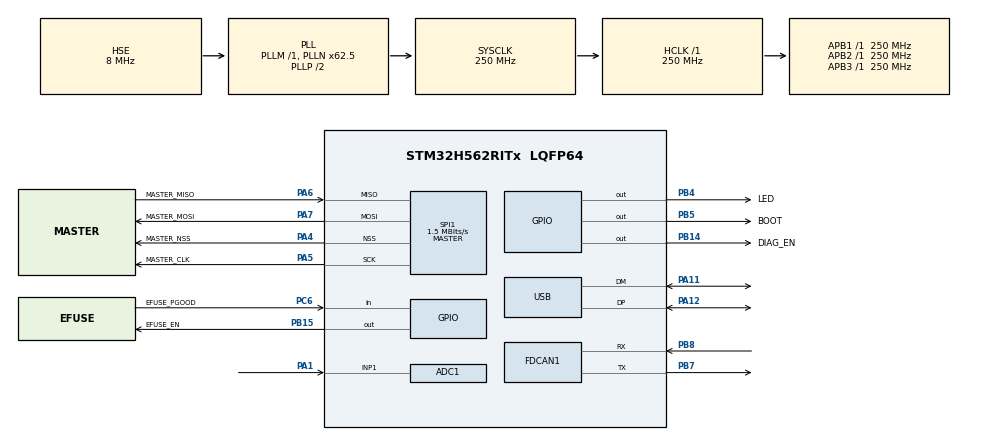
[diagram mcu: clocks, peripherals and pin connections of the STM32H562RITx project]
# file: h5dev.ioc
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ADC1.Channel-0\#ChannelRegularConversion=ADC_CHANNEL_1
ADC1.ContinuousConvMode=DISABLE
ADC1.ConversionDataManagement=ADC_CONVERSIONDATA_DMA_CIRCULAR
ADC1.DMAContinuousRequests=ENABLE
ADC1.EOCSelection=ADC_EOC_SEQ_CONV
ADC1.ExternalTrigConv=ADC_EXTERNALTRIG_T3_TRGO
ADC1.MonitoredBy-0\#ChannelRegularConversion=__NULL
ADC1.NbrOfConversionFlag=1
ADC1.OffsetNumber-0\#ChannelRegularConversion=ADC_OFFSET_NONE
ADC1.Rank-0\#ChannelRegularConversion=1
ADC1.SamplingTime-0\#ChannelRegularConversion=ADC_SAMPLETIME_2CYCLES_5
ADC1.master=1
BOOTPATH.BootPathName=LEGACY
BOOTPATH.UserSelectedBootPath=LEGACY
CORTEX_M33_NS.userName=CORTEX_M33
FDCAN1.AutoRetransmission=ENABLE
FDCAN1.CalculateBaudRateNominal=1000000
FDCAN1.CalculateTimeBitNominal=1000
FDCAN1.CalculateTimeQuantumNominal=62.5
FDCAN1.DataPrescaler=3
FDCAN1.DataSyncJumpWidth=2
FDCAN1.DataTimeSeg1=5
FDCAN1.DataTimeSeg2=2
FDCAN1.ExtFiltersNbr=1
FDCAN1.FrameFormat=FDCAN_FRAME_FD_NO_BRS
FDCAN1.Mode=FDCAN_MODE_NORMAL
FDCAN1.NominalPrescaler=6
FDCAN1.NominalSyncJumpWidth=2
FDCAN1.NominalTimeSeg1=13
FDCAN1.NominalTimeSeg2=2
FDCAN1.StdFiltersNbr=1
GPDMA1.CIRCULARMODE_GPDMACH0=ENABLE
GPDMA1.DESTDATAWIDTH_GPDMACH0=DMA_DEST_DATAWIDTH_HALFWORD
GPDMA1.IPHANDLE_GPDMACH0-SIMPLEREQUEST_GPDMACH0=__NULL
GPDMA1.REQUEST_GPDMACH0=GPDMA1_REQUEST_ADC1
GPDMA1.SRCDATAWIDTH_GPDMACH0=DMA_SRC_DATAWIDTH_HALFWORD
GPDMA1.TRIGGERPOLARITY_GPDMACH0=DMA_TRIG_POLARITY_MASKED
Mcu.Family=STM32H5
Mcu.Name=STM32H562RITx
Mcu.Package=LQFP64
NVIC.ADC1_IRQn=true\:5\:0\:true\:false\:true\:true\:true\:true
NVIC.FDCAN1_IT0_IRQn=true\:5\:0\:true\:false\:true\:true\:true\:true
NVIC.FDCAN1_IT1_IRQn=true\:5\:0\:true\:false\:true\:true\:true\:true
NVIC.GPDMA1_Channel0_IRQn=true\:5\:0\:true\:false\:true\:true\:true\:true
NVIC.PriorityGroup=NVIC_PRIORITYGROUP_4
NVIC.RCC_IRQn=true\:5\:0\:true\:false\:true\:true\:false\:true
NVIC.TIM3_IRQn=true\:5\:0\:true\:false\:true\:true\:true\:true
NVIC.TIM6_IRQn=true\:15\:0\:false\:false\:true\:false\:true\:true
NVIC.TimeBase=TIM6_IRQn
NVIC.TimeBaseIP=TIM6
NVIC.USB_DRD_FS_IRQn=true\:0\:0\:false\:false\:true\:true\:true\:true
PA1.Signal=ADCx_INP1
PA11.Mode=Device
PA11.Signal=USB_DM
PA12.Mode=Device
PA12.Signal=USB_DP
PA13(JTMS/SWDIO).GPIO_Label=SWDIO
PA13(JTMS/SWDIO).Mode=Trace_Asynchronous_SW
PA13(JTMS/SWDIO).Signal=DEBUG_JTMS-SWDIO
PA14(JTCK/SWCLK).GPIO_Label=SWCLK
PA14(JTCK/SWCLK).Mode=Trace_Asynchronous_SW
PA14(JTCK/SWCLK).Signal=DEBUG_JTCK-SWCLK
PA4.GPIO_Label=MASTER_NSS
PA4.Mode=NSS_Signal_Hard_Output
PA4.Signal=SPI1_NSS
PA5.GPIO_Label=MASTER_CLK
PA5.Mode=Full_Duplex_Master
PA5.Signal=SPI1_SCK
PA6.GPIO_Label=MASTER_MISO
PA6.Mode=Full_Duplex_Master
PA6.Signal=SPI1_MISO
PA7.GPIO_Label=MASTER_MOSI
PA7.Mode=Full_Duplex_Master
PA7.Signal=SPI1_MOSI
PA9.GPIO_Label=SLAVE_CLK
PA9.Signal=SPI2_SCK
PB14.GPIO_Label=DIAG_EN
PB14.Signal=GPIO_Output
PB15.GPIO_Label=EFUSE_EN
PB15.Signal=GPIO_Output
PB3(JTDO/TRACESWO).GPIO_Label=SWO
PB3(JTDO/TRACESWO).Mode=Trace_Asynchronous_SW
PB3(JTDO/TRACESWO).Signal=DEBUG_JTDO-SWO
PB4(NJTRST).GPIO_Label=LED
PB4(NJTRST).PinState=GPIO_PIN_RESET
PB4(NJTRST).Signal=GPIO_Output
PB5.GPIO_Label=BOOT
PB5.PinState=GPIO_PIN_RESET
PB5.Signal=GPIO_Output
PB7.Mode=FDCAN_Activate
PB7.Signal=FDCAN1_TX
PB8.Mode=FDCAN_Activate
PB8.Signal=FDCAN1_RX
PC14-OSC32_IN(OSC32_IN).Mode=LSE-External-Oscillator
PC14-OSC32_IN(OSC32_IN).Signal=RCC_OSC32_IN
PC15-OSC32_OUT(OSC32_OUT).Mode=LSE-External-Oscillator
PC15-OSC32_OUT(OSC32_OUT).Signal=RCC_OSC32_OUT
PC6.GPIO_Label=EFUSE_PGOOD
PC6.Signal=GPIO_Input
PH0-OSC_IN(PH0).Mode=HSE-External-Oscillator
PH0-OSC_IN(PH0).Signal=RCC_OSC_IN
PH1-OSC_OUT(PH1).Mode=HSE-External-Oscillator
PH1-OSC_OUT(PH1).Signal=RCC_OSC_OUT
ProjectManager.HeapSize=0x0
ProjectManager.StackSize=0x400
ProjectManager.TargetToolchain=CMake
RCC.ADCCLockSelection=RCC_ADCDACCLKSOURCE_PLL2R
RCC.ADCFreq_Value=96000000
RCC.AHBFreq_Value=250000000
RCC.APB1Freq_Value=250000000
RCC.APB1TimFreq_Value=250000000
RCC.APB2Freq_Value=250000000
RCC.APB2TimFreq_Value=250000000
RCC.APB3Freq_Value=250000000
RCC.CSI_VALUE=4000000
RCC.CortexFreq_Value=250000000
RCC.EPOD_VALUE=8000000
RCC.FDCANClockSelection=RCC_FDCANCLKSOURCE_PLL2Q
RCC.HCLKFreq_Value=250000000
RCC.HSE_VALUE=8000000
RCC.HSI48_VALUE=48000000
RCC.HSIDiv=RCC_HSI_DIV1
RCC.HSI_VALUE=64000000
RCC.LSIRC_VALUE=32000
RCC.PLL2FRACN=0
RCC.PLL2N=24
RCC.PLL2Source=RCC_PLL2_SOURCE_HSE
RCC.PLL3FRACN=4096
RCC.PLL3N=37
RCC.PLL3P=50
RCC.PLLFRACN=4096
RCC.PLLN=62
RCC.PLLSourceVirtual=RCC_PLL1_SOURCE_HSE
RCC.SPI1CLockSelection=RCC_SPI1CLKSOURCE_PLL3P
RCC.SPI2CLockSelection=RCC_SPI2CLKSOURCE_PLL3P
RCC.SYSCLKFreq_VALUE=250000000
RCC.SYSCLKSource=RCC_SYSCLKSOURCE_PLLCLK
RCC.USBFreq_Value=48000000
RCC.VCOOutputFreq_Value=500000000
SH.ADCx_INP1.0=ADC1_INP1,IN1-Single-Ended
SPI1.CalculateBaudRate=1.5 MBits/s
SPI1.DataSize=SPI_DATASIZE_8BIT
SPI1.Direction=SPI_DIRECTION_2LINES
SPI1.Mode=SPI_MODE_MASTER
SPI1.VirtualNSS=VM_NSSHARD
SPI1.VirtualType=VM_MASTER
TIM3.AutoReloadPreload=TIM_AUTORELOAD_PRELOAD_ENABLE
TIM3.PeriodNoDither=47999
TIM3.TIM_MasterOutputTrigger=TIM_TRGO_UPDATE
USB.VirtualMode=Device_Only
VP_BOOTPATH_VS_BOOTPATH.Mode=BP_Activate
VP_CORDIC_VS_CORDIC.Mode=CORDIC_Activate
VP_CORTEX_M33_NS_VS_Ext.Mode=External_Mode
VP_GPDMA1_VS_GPDMACH0.Mode=SIMPLEREQUEST_GPDMACH0
VP_MEMORYMAP_VS_MEMORYMAP.Mode=CurAppReg
VP_PWR_VS_LPOM.Mode=PowerOptimisation
VP_PWR_VS_SECSignals.Mode=Security/Privilege
VP_RTC_VS_RTC_Activate.Mode=RTC_Enabled
VP_SYS_VS_tim6.Mode=TIM6
VP_TIM3_VS_ClockSourceINT.Mode=Internal
board=custom

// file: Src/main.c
/* USER CODE BEGIN Header */
/**
 ******************************************************************************
 * @file           : main.c
 * @brief          : Main program body
 ******************************************************************************
 * @attention
 *
 * Copyright (c) 2026 STMicroelectronics.
 * All rights reserved.
 *
 * This software is licensed under terms that can be found in the LICENSE file
 * in the root directory of this software component.
 * If no LICENSE file comes with this software, it is provided AS-IS.
 *
 ******************************************************************************
 */
/* USER CODE END Header */
#include "main.h"

/* USER CODE BEGIN Includes */
#include "tasks.h"
#include "hw_usb.h"
#include "hw_error.hpp"
#include "SEGGER_SYSVIEW.h"
/* USER CODE END Includes */

ADC_HandleTypeDef hadc1;
DMA_NodeTypeDef   Node_GPDMA1_Channel0;
DMA_QListTypeDef  List_GPDMA1_Channel0;
DMA_HandleTypeDef handle_GPDMA1_Channel0;

CORDIC_HandleTypeDef hcordic;

FDCAN_HandleTypeDef hfdcan1;

RTC_HandleTypeDef hrtc;

SPI_HandleTypeDef hspi1;

TIM_HandleTypeDef htim3;

PCD_HandleTypeDef hpcd_USB_DRD_FS;

void        SystemClock_Config(void);
void        PeriphCommonClock_Config(void);
static void MX_GPIO_Init(void);
static void MX_GPDMA1_Init(void);
static void MX_FDCAN1_Init(void);
static void MX_RTC_Init(void);
static void MX_USB_PCD_Init(void);
static void MX_ADC1_Init(void);
static void MX_SPI1_Init(void);
static void MX_TIM3_Init(void);
static void MX_CORDIC_Init(void);

int main(void)
{
    /* USER CODE BEGIN 1 */
    tasks_preInit();
    /* USER CODE END 1 */

    /* MCU Configuration--------------------------------------------------------*/

    /* Reset of all peripherals, Initializes the Flash interface and the Systick. */
    HAL_Init();

    /* Configure the system clock */
    SystemClock_Config();

    /* Configure the peripherals common clocks */
    PeriphCommonClock_Config();

    /* Initialize all configured peripherals */
    MX_GPIO_Init();
    MX_GPDMA1_Init();
    MX_FDCAN1_Init();
    MX_RTC_Init();
    MX_USB_PCD_Init();
    MX_ADC1_Init();
    MX_SPI1_Init();
    MX_TIM3_Init();
    MX_CORDIC_Init();
    /* USER CODE BEGIN 2 */
    tasks_init();
    /* USER CODE END 2 */

    /* Infinite loop */
    while (1)
    {

    }
}

void SystemClock_Config(void)
{
    RCC_OscInitTypeDef RCC_OscInitStruct = { 0 };
    RCC_ClkInitTypeDef RCC_ClkInitStruct = { 0 };

    /** Configure the main internal regulator output voltage
     */
    __HAL_PWR_VOLTAGESCALING_CONFIG(PWR_REGULATOR_VOLTAGE_SCALE0);

    while (!__HAL_PWR_GET_FLAG(PWR_FLAG_VOSRDY))
    {
    }

    /** Initializes the RCC Oscillators according to the specified parameters
     * in the RCC_OscInitTypeDef structure.
     */
    RCC_OscInitStruct.OscillatorType =
        RCC_OSCILLATORTYPE_HSI48 | RCC_OSCILLATORTYPE_LSI | RCC_OSCILLATORTYPE_HSE | RCC_OSCILLATORTYPE_CSI;
    RCC_OscInitStruct.HSEState            = RCC_HSE_ON;
    RCC_OscInitStruct.LSIState            = RCC_LSI_ON;
    RCC_OscInitStruct.HSI48State          = RCC_HSI48_ON;
    RCC_OscInitStruct.CSIState            = RCC_CSI_ON;
    RCC_OscInitStruct.CSICalibrationValue = RCC_CSICALIBRATION_DEFAULT;
    RCC_OscInitStruct.PLL.PLLState        = RCC_PLL_ON;
    RCC_OscInitStruct.PLL.PLLSource       = RCC_PLL1_SOURCE_HSE;
    RCC_OscInitStruct.PLL.PLLM            = 1;
    RCC_OscInitStruct.PLL.PLLN            = 62;
    RCC_OscInitStruct.PLL.PLLP            = 2;
    RCC_OscInitStruct.PLL.PLLQ            = 2;
    RCC_OscInitStruct.PLL.PLLR            = 2;
    RCC_OscInitStruct.PLL.PLLRGE          = RCC_PLL1_VCIRANGE_3;
    RCC_OscInitStruct.PLL.PLLVCOSEL       = RCC_PLL1_VCORANGE_WIDE;
    RCC_OscInitStruct.PLL.PLLFRACN        = 4096;
    if (HAL_RCC_OscConfig(&RCC_OscInitStruct) != HAL_OK)
    {
        Error_Handler();
    }

    /** Initializes the CPU, AHB and APB buses clocks
     */
    RCC_ClkInitStruct.ClockType =
        RCC_CLOCKTYPE_HCLK | RCC_CLOCKTYPE_SYSCLK | RCC_CLOCKTYPE_PCLK1 | RCC_CLOCKTYPE_PCLK2 | RCC_CLOCKTYPE_PCLK3;
    RCC_ClkInitStruct.SYSCLKSource   = RCC_SYSCLKSOURCE_PLLCLK;
    RCC_ClkInitStruct.AHBCLKDivider  = RCC_SYSCLK_DIV1;
    RCC_ClkInitStruct.APB1CLKDivider = RCC_HCLK_DIV1;
    RCC_ClkInitStruct.APB2CLKDivider = RCC_HCLK_DIV1;
    RCC_ClkInitStruct.APB3CLKDivider = RCC_HCLK_DIV1;

    if (HAL_RCC_ClockConfig(&RCC_ClkInitStruct, FLASH_LATENCY_5) != HAL_OK)
    {
        Error_Handler();
    }

    /* Select SysTick source clock */
    HAL_SYSTICK_CLKSourceConfig(SYSTICK_CLKSOURCE_HCLK);

    /* Re-Initialize Tick with new clock source */
    if (HAL_InitTick(TICK_INT_PRIORITY) != HAL_OK)
    {
        Error_Handler();
    }

    /** Configure the programming delay
     */
    __HAL_FLASH_SET_PROGRAM_DELAY(FLASH_PROGRAMMING_DELAY_2);
}

void PeriphCommonClock_Config(void)
{
    RCC_PeriphCLKInitTypeDef PeriphClkInitStruct = { 0 };

    /** Initializes the peripherals clock
     */
    PeriphClkInitStruct.PeriphClockSelection = RCC_PERIPHCLK_ADCDAC | RCC_PERIPHCLK_FDCAN;
    PeriphClkInitStruct.PLL2.PLL2Source      = RCC_PLL2_SOURCE_HSE;
    PeriphClkInitStruct.PLL2.PLL2M           = 1;
    PeriphClkInitStruct.PLL2.PLL2N           = 24;
    PeriphClkInitStruct.PLL2.PLL2P           = 2;
    PeriphClkInitStruct.PLL2.PLL2Q           = 2;
    PeriphClkInitStruct.PLL2.PLL2R           = 2;
    PeriphClkInitStruct.PLL2.PLL2RGE         = RCC_PLL2_VCIRANGE_3;
    PeriphClkInitStruct.PLL2.PLL2VCOSEL      = RCC_PLL2_VCORANGE_WIDE;
    PeriphClkInitStruct.PLL2.PLL2FRACN       = 0;
    PeriphClkInitStruct.PLL2.PLL2ClockOut    = RCC_PLL2_DIVQ | RCC_PLL2_DIVR;
    PeriphClkInitStruct.FdcanClockSelection  = RCC_FDCANCLKSOURCE_PLL2Q;
    PeriphClkInitStruct.AdcDacClockSelection = RCC_ADCDACCLKSOURCE_PLL2R;
    if (HAL_RCCEx_PeriphCLKConfig(&PeriphClkInitStruct) != HAL_OK)
    {
        Error_Handler();
    }
}

static void MX_ADC1_Init(void)
{

    ADC_ChannelConfTypeDef sConfig = { 0 };

    /** Common config
     */
    hadc1.Instance                   = ADC1;
    hadc1.Init.ClockPrescaler        = ADC_CLOCK_ASYNC_DIV2;
    hadc1.Init.Resolution            = ADC_RESOLUTION_12B;
    hadc1.Init.DataAlign             = ADC_DATAALIGN_RIGHT;
    hadc1.Init.ScanConvMode          = ADC_SCAN_DISABLE;
    hadc1.Init.EOCSelection          = ADC_EOC_SEQ_CONV;
    hadc1.Init.LowPowerAutoWait      = DISABLE;
    hadc1.Init.ContinuousConvMode    = DISABLE;
    hadc1.Init.NbrOfConversion       = 1;
    hadc1.Init.DiscontinuousConvMode = DISABLE;
    hadc1.Init.ExternalTrigConv      = ADC_EXTERNALTRIG_T3_TRGO;
    hadc1.Init.ExternalTrigConvEdge  = ADC_EXTERNALTRIGCONVEDGE_RISING;
    hadc1.Init.DMAContinuousRequests = ENABLE;
    hadc1.Init.SamplingMode          = ADC_SAMPLING_MODE_NORMAL;
    hadc1.Init.Overrun               = ADC_OVR_DATA_PRESERVED;
    hadc1.Init.OversamplingMode      = DISABLE;
    if (HAL_ADC_Init(&hadc1) != HAL_OK)
    {
        Error_Handler();
    }

    /** Configure Regular Channel
     */
    sConfig.Channel      = ADC_CHANNEL_1;
    sConfig.Rank         = ADC_REGULAR_RANK_1;
    sConfig.SamplingTime = ADC_SAMPLETIME_2CYCLES_5;
    sConfig.SingleDiff   = ADC_SINGLE_ENDED;
    sConfig.OffsetNumber = ADC_OFFSET_NONE;
    sConfig.Offset       = 0;
    if (HAL_ADC_ConfigChannel(&hadc1, &sConfig) != HAL_OK)
    {
        Error_Handler();
    }
}

static void MX_CORDIC_Init(void)
{

    hcordic.Instance = CORDIC;
    if (HAL_CORDIC_Init(&hcordic) != HAL_OK)
    {
        Error_Handler();
    }
}

static void MX_FDCAN1_Init(void)
{

    hfdcan1.Instance                  = FDCAN1;
    hfdcan1.Init.ClockDivider         = FDCAN_CLOCK_DIV1;
    hfdcan1.Init.FrameFormat          = FDCAN_FRAME_FD_NO_BRS;
    hfdcan1.Init.Mode                 = FDCAN_MODE_NORMAL;
    hfdcan1.Init.AutoRetransmission   = ENABLE;
    hfdcan1.Init.TransmitPause        = DISABLE;
    hfdcan1.Init.ProtocolException    = DISABLE;
    hfdcan1.Init.NominalPrescaler     = 6;
    hfdcan1.Init.NominalSyncJumpWidth = 2;
    hfdcan1.Init.NominalTimeSeg1      = 13;
    hfdcan1.Init.NominalTimeSeg2      = 2;
    hfdcan1.Init.DataPrescaler        = 3;
    hfdcan1.Init.DataSyncJumpWidth    = 2;
    hfdcan1.Init.DataTimeSeg1         = 5;
    hfdcan1.Init.DataTimeSeg2         = 2;
    hfdcan1.Init.StdFiltersNbr        = 1;
    hfdcan1.Init.ExtFiltersNbr        = 1;
    hfdcan1.Init.TxFifoQueueMode      = FDCAN_TX_FIFO_OPERATION;
    if (HAL_FDCAN_Init(&hfdcan1) != HAL_OK)
    {
        Error_Handler();
    }
}

static void MX_GPDMA1_Init(void)
{

    /* Peripheral clock enable */
    __HAL_RCC_GPDMA1_CLK_ENABLE();

    /* GPDMA1 interrupt Init */
    HAL_NVIC_SetPriority(GPDMA1_Channel0_IRQn, 5, 0);
    HAL_NVIC_EnableIRQ(GPDMA1_Channel0_IRQn);

}

static void MX_RTC_Init(void)
{

    RTC_PrivilegeStateTypeDef privilegeState = { 0 };

    /** Initialize RTC Only
     */
    hrtc.Instance            = RTC;
    hrtc.Init.HourFormat     = RTC_HOURFORMAT_24;
    hrtc.Init.AsynchPrediv   = 127;
    hrtc.Init.SynchPrediv    = 255;
    hrtc.Init.OutPut         = RTC_OUTPUT_DISABLE;
    hrtc.Init.OutPutRemap    = RTC_OUTPUT_REMAP_NONE;
    hrtc.Init.OutPutPolarity = RTC_OUTPUT_POLARITY_HIGH;
    hrtc.Init.OutPutType     = RTC_OUTPUT_TYPE_OPENDRAIN;
    hrtc.Init.OutPutPullUp   = RTC_OUTPUT_PULLUP_NONE;
    hrtc.Init.BinMode        = RTC_BINARY_NONE;
    if (HAL_RTC_Init(&hrtc) != HAL_OK)
    {
        Error_Handler();
    }
    privilegeState.rtcPrivilegeFull         = RTC_PRIVILEGE_FULL_NO;
    privilegeState.backupRegisterPrivZone   = RTC_PRIVILEGE_BKUP_ZONE_NONE;
    privilegeState.backupRegisterStartZone2 = RTC_BKP_DR0;
    privilegeState.backupRegisterStartZone3 = RTC_BKP_DR0;
    if (HAL_RTCEx_PrivilegeModeSet(&hrtc, &privilegeState) != HAL_OK)
    {
        Error_Handler();
    }
}

static void MX_SPI1_Init(void)
{

    /* SPI1 parameter configuration*/
    hspi1.Instance                     = SPI1;
    hspi1.Init.Mode                    = SPI_MODE_MASTER;
    hspi1.Init.Direction               = SPI_DIRECTION_2LINES;
    hspi1.Init.DataSize                = SPI_DATASIZE_8BIT;
    hspi1.Init.CLKPolarity             = SPI_POLARITY_LOW;
    hspi1.Init.CLKPhase                = SPI_PHASE_1EDGE;
    hspi1.Init.NSS                     = SPI_NSS_HARD_OUTPUT;
    hspi1.Init.BaudRatePrescaler       = SPI_BAUDRATEPRESCALER_2;
    hspi1.Init.FirstBit                = SPI_FIRSTBIT_MSB;
    hspi1.Init.TIMode                  = SPI_TIMODE_DISABLE;
    hspi1.Init.CRCCalculation          = SPI_CRCCALCULATION_DISABLE;
    hspi1.Init.CRCPolynomial           = 0x7;
    hspi1.Init.NSSPMode                = SPI_NSS_PULSE_ENABLE;
    hspi1.Init.NSSPolarity             = SPI_NSS_POLARITY_LOW;
    hspi1.Init.FifoThreshold           = SPI_FIFO_THRESHOLD_01DATA;
    hspi1.Init.MasterSSIdleness        = SPI_MASTER_SS_IDLENESS_00CYCLE;
    hspi1.Init.MasterInterDataIdleness = SPI_MASTER_INTERDATA_IDLENESS_00CYCLE;
    hspi1.Init.MasterReceiverAutoSusp  = SPI_MASTER_RX_AUTOSUSP_DISABLE;
    hspi1.Init.MasterKeepIOState       = SPI_MASTER_KEEP_IO_STATE_DISABLE;
    hspi1.Init.IOSwap                  = SPI_IO_SWAP_DISABLE;
    hspi1.Init.ReadyMasterManagement   = SPI_RDY_MASTER_MANAGEMENT_INTERNALLY;
    hspi1.Init.ReadyPolarity           = SPI_RDY_POLARITY_HIGH;
    if (HAL_SPI_Init(&hspi1) != HAL_OK)
    {
        Error_Handler();
    }
}

static void MX_TIM3_Init(void)
{

    TIM_ClockConfigTypeDef  sClockSourceConfig = { 0 };
    TIM_MasterConfigTypeDef sMasterConfig      = { 0 };

    htim3.Instance               = TIM3;
    htim3.Init.Prescaler         = 0;
    htim3.Init.CounterMode       = TIM_COUNTERMODE_UP;
    htim3.Init.Period            = 47999;
    htim3.Init.ClockDivision     = TIM_CLOCKDIVISION_DIV1;
    htim3.Init.AutoReloadPreload = TIM_AUTORELOAD_PRELOAD_ENABLE;
    if (HAL_TIM_Base_Init(&htim3) != HAL_OK)
    {
        Error_Handler();
    }
    sClockSourceConfig.ClockSource = TIM_CLOCKSOURCE_INTERNAL;
    if (HAL_TIM_ConfigClockSource(&htim3, &sClockSourceConfig) != HAL_OK)
    {
        Error_Handler();
    }
    sMasterConfig.MasterOutputTrigger = TIM_TRGO_UPDATE;
    sMasterConfig.MasterSlaveMode     = TIM_MASTERSLAVEMODE_DISABLE;
    if (HAL_TIMEx_MasterConfigSynchronization(&htim3, &sMasterConfig) != HAL_OK)
    {
        Error_Handler();
    }
}

static void MX_USB_PCD_Init(void)
{

    hpcd_USB_DRD_FS.Instance                      = USB_DRD_FS;
    hpcd_USB_DRD_FS.Init.dev_endpoints            = 8;
    hpcd_USB_DRD_FS.Init.speed                    = USBD_FS_SPEED;
    hpcd_USB_DRD_FS.Init.phy_itface               = PCD_PHY_EMBEDDED;
    hpcd_USB_DRD_FS.Init.Sof_enable               = DISABLE;
    hpcd_USB_DRD_FS.Init.low_power_enable         = DISABLE;
    hpcd_USB_DRD_FS.Init.lpm_enable               = DISABLE;
    hpcd_USB_DRD_FS.Init.battery_charging_enable  = DISABLE;
    hpcd_USB_DRD_FS.Init.vbus_sensing_enable      = DISABLE;
    hpcd_USB_DRD_FS.Init.bulk_doublebuffer_enable = DISABLE;
    hpcd_USB_DRD_FS.Init.iso_singlebuffer_enable  = DISABLE;
    if (HAL_PCD_Init(&hpcd_USB_DRD_FS) != HAL_OK)
    {
        Error_Handler();
    }
}

static void MX_GPIO_Init(void)
{
    GPIO_InitTypeDef GPIO_InitStruct = { 0 };

    /* GPIO Ports Clock Enable */
    __HAL_RCC_GPIOC_CLK_ENABLE();
    __HAL_RCC_GPIOH_CLK_ENABLE();
    __HAL_RCC_GPIOA_CLK_ENABLE();
    __HAL_RCC_GPIOB_CLK_ENABLE();

    /*Configure GPIO pin Output Level */
    HAL_GPIO_WritePin(GPIOB, DIAG_EN_Pin | EFUSE_EN_Pin | LED_Pin | BOOT_Pin, GPIO_PIN_RESET);

    /*Configure GPIO pins : DIAG_EN_Pin EFUSE_EN_Pin LED_Pin BOOT_Pin */
    GPIO_InitStruct.Pin   = DIAG_EN_Pin | EFUSE_EN_Pin | LED_Pin | BOOT_Pin;
    GPIO_InitStruct.Mode  = GPIO_MODE_OUTPUT_PP;
    GPIO_InitStruct.Pull  = GPIO_NOPULL;
    GPIO_InitStruct.Speed = GPIO_SPEED_FREQ_LOW;
    HAL_GPIO_Init(GPIOB, &GPIO_InitStruct);

    /*Configure GPIO pin : EFUSE_PGOOD_Pin */
    GPIO_InitStruct.Pin  = EFUSE_PGOOD_Pin;
    GPIO_InitStruct.Mode = GPIO_MODE_INPUT;
    GPIO_InitStruct.Pull = GPIO_NOPULL;
    HAL_GPIO_Init(EFUSE_PGOOD_GPIO_Port, &GPIO_InitStruct);

    /*Configure GPIO pin : SLAVE_CLK_Pin */
    GPIO_InitStruct.Pin       = SLAVE_CLK_Pin;
    GPIO_InitStruct.Mode      = GPIO_MODE_AF_PP;
    GPIO_InitStruct.Pull      = GPIO_NOPULL;
    GPIO_InitStruct.Speed     = GPIO_SPEED_FREQ_LOW;
    GPIO_InitStruct.Alternate = GPIO_AF5_SPI2;
    HAL_GPIO_Init(SLAVE_CLK_GPIO_Port, &GPIO_InitStruct);

}

void HAL_TIM_PeriodElapsedCallback(TIM_HandleTypeDef *htim)
{
    if (htim->Instance == TIM6)
    {
        HAL_IncTick();
    }
}

void Error_Handler(void)
{
    __disable_irq();
    while (1)
    {
    }
}
